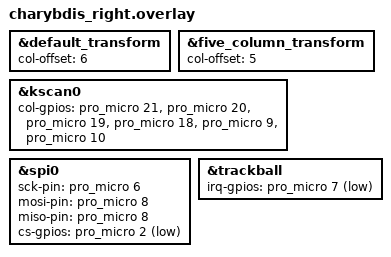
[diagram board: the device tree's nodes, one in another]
#include "charybdis.dtsi"

&default_transform {
	col-offset = <6>;
};

&five_column_transform {
	col-offset = <5>;
};

&kscan0 {
	col-gpios
		= <&pro_micro 21 (GPIO_ACTIVE_HIGH | GPIO_PULL_DOWN)>
		, <&pro_micro 20 (GPIO_ACTIVE_HIGH | GPIO_PULL_DOWN)>
		, <&pro_micro 19 (GPIO_ACTIVE_HIGH | GPIO_PULL_DOWN)>
		, <&pro_micro 18 (GPIO_ACTIVE_HIGH | GPIO_PULL_DOWN)>
		, <&pro_micro 9 (GPIO_ACTIVE_HIGH | GPIO_PULL_DOWN)>
		, <&pro_micro 10 (GPIO_ACTIVE_HIGH | GPIO_PULL_DOWN)>
		;
};

// trackball bus
&spi0 {
	status = "okay"; //okay
	sck-pin = <&pro_micro 6>;
	mosi-pin = <&pro_micro 8>;
	miso-pin = <&pro_micro 8>; // same as mosi (3-wire spi)
	cs-gpios = <&pro_micro 2 GPIO_ACTIVE_LOW>;
};

&trackball {
	status = "okay"; //okay
	irq-gpios = <&pro_micro 7 (GPIO_ACTIVE_LOW | GPIO_PULL_UP)>;
};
